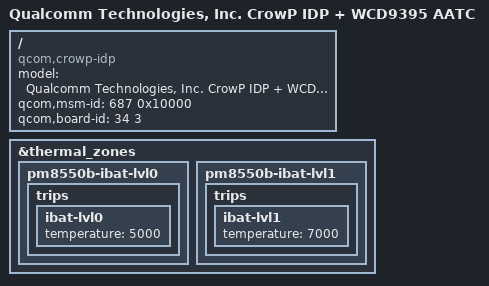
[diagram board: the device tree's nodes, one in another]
/dts-v1/;
/plugin/;

#include "crowp-idp-wcd9395-aatc.dtsi"
#include "crow-idp-pm8550b.dtsi"

/ {
	model = "Qualcomm Technologies, Inc. CrowP IDP + WCD9395 AATC";
	compatible = "qcom,crowp-idp", "qcom,crowp", "qcom,idp";
	qcom,msm-id = <687 0x10000>;
	qcom,board-id = <34 3>;
};

&thermal_zones {
	pm8550b-ibat-lvl0 {
		trips {
			ibat-lvl0 {
				temperature = <5000>;
			};
		};
	};

	pm8550b-ibat-lvl1 {
		trips {
			ibat-lvl1 {
				temperature = <7000>;
			};
		};
	};
};
